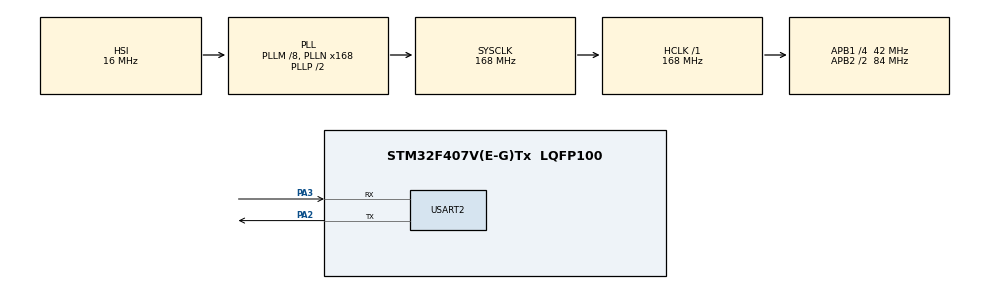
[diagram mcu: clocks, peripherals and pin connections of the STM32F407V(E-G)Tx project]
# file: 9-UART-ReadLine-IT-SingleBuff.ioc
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Mcu.Family=STM32F4
Mcu.Name=STM32F407V(E-G)Tx
Mcu.Package=LQFP100
NVIC.PriorityGroup=NVIC_PRIORITYGROUP_4
NVIC.USART2_IRQn=true\:0\:0\:false\:false\:true\:true\:true\:true
PA2.Mode=Asynchronous
PA2.Signal=USART2_TX
PA3.Mode=Asynchronous
PA3.Signal=USART2_RX
ProjectManager.HeapSize=0x200
ProjectManager.StackSize=0x400
ProjectManager.TargetToolchain=STM32CubeIDE
RCC.48MHZClocksFreq_Value=84000000
RCC.AHBFreq_Value=168000000
RCC.APB1CLKDivider=RCC_HCLK_DIV4
RCC.APB1Freq_Value=42000000
RCC.APB1TimFreq_Value=84000000
RCC.APB2CLKDivider=RCC_HCLK_DIV2
RCC.APB2Freq_Value=84000000
RCC.APB2TimFreq_Value=168000000
RCC.CortexFreq_Value=168000000
RCC.HCLKFreq_Value=168000000
RCC.HSE_VALUE=25000000
RCC.HSI_VALUE=16000000
RCC.LSE_VALUE=32768
RCC.PLLM=8
RCC.PLLN=168
RCC.SYSCLKFreq_VALUE=168000000
RCC.SYSCLKSource=RCC_SYSCLKSOURCE_PLLCLK
RCC.VCOOutputFreq_Value=336000000
USART2.VirtualMode=VM_ASYNC
board=custom

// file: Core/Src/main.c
/* USER CODE BEGIN Header */
/**
  ******************************************************************************
  * @file           : main.c
  * @brief          : Main program body
  ******************************************************************************
  * @attention
  *
  * Copyright (c) 2026 STMicroelectronics.
  * All rights reserved.
  *
  * This software is licensed under terms that can be found in the LICENSE file
  * in the root directory of this software component.
  * If no LICENSE file comes with this software, it is provided AS-IS.
  *
  ******************************************************************************
  */
/* USER CODE END Header */
#include "main.h"
#include "usart.h"
#include "gpio.h"

/* USER CODE BEGIN PD */

#define RX_BUF_SIZE	64

/* USER CODE END PD */

/* USER CODE BEGIN PV */

static uint8_t rxBuf[RX_BUF_SIZE] = {0};
static uint16_t rxBufIndex = 0;
static uint8_t rxTemp = 0;

static uint8_t rxFlag = 0;

/* USER CODE END PV */

void SystemClock_Config(void);

int main(void)
{

  /* MCU Configuration--------------------------------------------------------*/

  /* Reset of all peripherals, Initializes the Flash interface and the Systick. */
  HAL_Init();

  /* Configure the system clock */
  SystemClock_Config();

  /* Initialize all configured peripherals */
  MX_GPIO_Init();
  MX_USART2_UART_Init();

  /* Infinite loop */
  /* USER CODE BEGIN WHILE */

  HAL_UART_Receive_IT(&huart2, &rxTemp, sizeof(rxTemp));

  while (1)
  {

	  if(rxFlag)
	  {
		  rxFlag = 0;
		  //Process
		  HAL_UART_Transmit_IT(&huart2, rxBuf, rxBufIndex);
		  //Reset Variables
		  rxBufIndex = 0;
	  }

    /* USER CODE END WHILE */

  }
}

void SystemClock_Config(void)
{
  RCC_OscInitTypeDef RCC_OscInitStruct = {0};
  RCC_ClkInitTypeDef RCC_ClkInitStruct = {0};

  /** Configure the main internal regulator output voltage
  */
  __HAL_RCC_PWR_CLK_ENABLE();
  __HAL_PWR_VOLTAGESCALING_CONFIG(PWR_REGULATOR_VOLTAGE_SCALE1);

  /** Initializes the RCC Oscillators according to the specified parameters
  * in the RCC_OscInitTypeDef structure.
  */
  RCC_OscInitStruct.OscillatorType = RCC_OSCILLATORTYPE_HSI;
  RCC_OscInitStruct.HSIState = RCC_HSI_ON;
  RCC_OscInitStruct.HSICalibrationValue = RCC_HSICALIBRATION_DEFAULT;
  RCC_OscInitStruct.PLL.PLLState = RCC_PLL_ON;
  RCC_OscInitStruct.PLL.PLLSource = RCC_PLLSOURCE_HSI;
  RCC_OscInitStruct.PLL.PLLM = 8;
  RCC_OscInitStruct.PLL.PLLN = 168;
  RCC_OscInitStruct.PLL.PLLP = RCC_PLLP_DIV2;
  RCC_OscInitStruct.PLL.PLLQ = 4;
  if (HAL_RCC_OscConfig(&RCC_OscInitStruct) != HAL_OK)
  {
    Error_Handler();
  }

  /** Initializes the CPU, AHB and APB buses clocks
  */
  RCC_ClkInitStruct.ClockType = RCC_CLOCKTYPE_HCLK|RCC_CLOCKTYPE_SYSCLK
                              |RCC_CLOCKTYPE_PCLK1|RCC_CLOCKTYPE_PCLK2;
  RCC_ClkInitStruct.SYSCLKSource = RCC_SYSCLKSOURCE_PLLCLK;
  RCC_ClkInitStruct.AHBCLKDivider = RCC_SYSCLK_DIV1;
  RCC_ClkInitStruct.APB1CLKDivider = RCC_HCLK_DIV4;
  RCC_ClkInitStruct.APB2CLKDivider = RCC_HCLK_DIV2;

  if (HAL_RCC_ClockConfig(&RCC_ClkInitStruct, FLASH_LATENCY_5) != HAL_OK)
  {
    Error_Handler();
  }
}

/* USER CODE BEGIN 4 */

void HAL_UART_RxCpltCallback(UART_HandleTypeDef* huart)
{
	switch ((uint32_t) huart -> Instance) {
		case USART2_BASE:
			//Store Byte in Buffer
			rxBuf[rxBufIndex++] = rxTemp;
			//Check for CRLF = "\r\n" = 0x0D 0x0A
			if (rxTemp == '\n'  &&
				rxBufIndex >= 2 &&
				rxBuf[rxBufIndex - 2] == '\r') {

				rxFlag = 1;
			}
			//Receive Next Byte
			HAL_UART_Receive_IT(&huart2, &rxTemp, sizeof(rxTemp));

			break;
		default:
			break;
	}
}

/* USER CODE END 4 */

void Error_Handler(void)
{
  __disable_irq();
  while (1)
  {
  }
}
